# RN831X_RN861X_MCU register map
File version: v0.0.1
CPU: RN831X_RN861X_MCU r1p0, little endian, MPU, no FPU
Registers are 32-bit, read-write, reset 0x0 unless marked. A register's access mark holds for its fields unless they carry their own. Offsets are from the block's base; [hi:lo] are bit positions; {n}, {i} and the like mark numbered series.

## DSP_CORE0 — DSP Module core0
Base 0x2006C000
Same registers: DSP_CORE1 0xA006C000
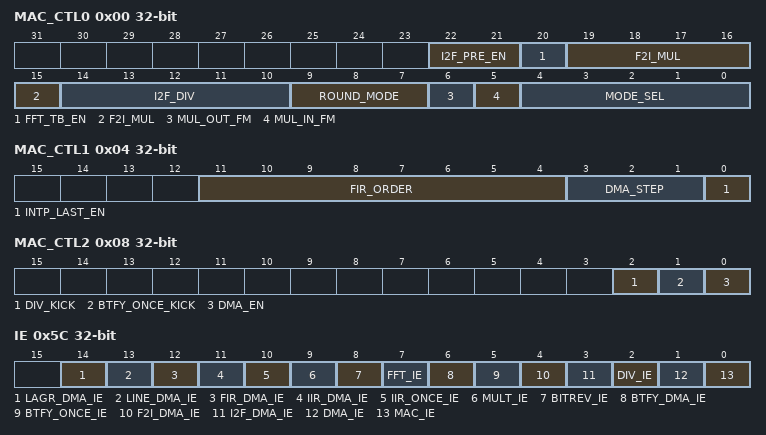
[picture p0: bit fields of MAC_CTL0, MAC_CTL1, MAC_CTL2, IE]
0x00 MAC_CTL0 — Control register_0 of Multiply-Accumulate unit
  [22:21] I2F_PRE_EN — Enable bits of Floating-To-Int preprocess
    0=4BYTE (I2F input data 4 byte available); 1=3BYTE (I2F input data low 3 byte available); 2=2BYTE (I2F input data low 2 byte available); 3=1BYTE (I2F input data low 1 byte available)
  [20] FFT_TB_EN — Enable bit of FFT internal table
  [19:15] F2I_MUL — Magnification order bit of floating point before Floating-To-Int
  [14:10] I2F_DIV — Normalized order bit of floating point after Int-To-Floating
  [9:7] ROUND_MODE — Round mode configuration bits
    0=NEAREST (Select round mode as nearest); 1=ZERO (Select round mode as zero); 2=P_INF (Select round mode as positive infinity); 3=N_INF (Select round mode as negative infinity); 4=UP (Select round mode as nearst up); 5=AWAY (Select round mode as away from zero)
  [6] MUL_OUT_FM — Output format bit of multiplication unit
    0=FLOAT (Select multiplication output format as float); 1=INT (Select multiplication output format as int)
  [5] MUL_IN_FM — Input format bit of multiplication unit
    0=FLOAT (Select multiplication input format as float); 1=INT (Select multiplication input format as int)
  [4:0] MODE_SEL — Select bits of DSP mode
    0=DIS (disable all mode of MAC unit); 1=I2F_ONCE (int to float conversion one-shot mode enable); 2=I2F_DMA (int to float conversion DMA mode enable); 3=F2I_ONCE (float to int conversion one-shot mode enable); 4=F2I_DMA (float to int conversion DMA mode enable); 5=FP_MUL (float multiply mode enable); 6=FP_ADD (float addition mode enable); 7=FP_SUB (float subtraction mode enable); 8=FP_MLAD (float multiplication and addition mode enable); 9=BTFY_ONCE (Butterfly operation unit one-shot mode enable); 10=BTFY_DMA (Butterfly operation unit DMA mode enable); 11=FFT (FFT mode enable); 12=BIT_RV (bit reverse mode enable); 13=IIR_ONCE (2nd IIR filter one-shot mode enable); 14=IIR_DMA (2nd IIR filter DMA mode enable); 15=FIR_DMA (FIR filter mode enable); 16=LINE_INTP (linear interpolation mode enable); 17=LAGR_INTP (Lagrange interpolation mode enable)
0x04 MAC_CTL1 — Control register_1 of Multiply-Accumulate unit
  [11:4] FIR_ORDER — FIR filter order configuration bits
  [3:1] DMA_STEP — Step of DMA read data from SRAM configuration bits (only available for IIR/FIR DMA mode )
    {v}=STEP_{v+1} (Configure DMA data step as {v+1}) (v=0..7)
  [0] INTP_LAST_EN — Interpolation mode using last data of last period enable bit
0x08 MAC_CTL2 access per field — Control register_2 of Multiply-Accumulate unit
  [2] DIV_KICK wo — Enable bit of division unit
  [1] BTFY_ONCE_KICK wo — Enable bit of butterfly once calculate
  [0] DMA_EN rw — Enable bit of DMA
{0xC+4i} MAC_IN{i} access not given (i=0..5) — Input register_{i} of Multiply-Accumulate unit
  [31:0] MAC_IN{i} — Input register_{i} bits of Multiply-Accumulate unit
{0x24+4i} MAC_OUT{i} access not given (i=0..3) — Output register_{i} of Multiply-Accumulate unit
  [31:0] MAC_OUT{i} — Output register_{i} bits of Multiply-Accumulate unit
0x34 DIV_IN0 access not given — Input register_0 of division unit
  [31:0] DIV_IN0 — Input register_0 bits of division unit
0x38 DIV_IN1 access not given — Input register_1 of division unit
  [31:0] DIV_IN1 — Input register_1 bits of division unit
0x3C DIV_OUT0 access not given — Output register_0 of division unit
  [31:0] DIV_OUT0 — Output register_0 bits of division unit
0x40 DMA_SRBADR access not given — Source address register of DMA and FFT real part
  [15:0] DMA_SRBADR — Source address register bits of DMA and FFT real part
0x44 DMA_SIBADR access not given — Source address register of FFT image part
  [15:0] DMA_SIBADR — Source address register bits of FFT image part
0x48 DMA_PRBADR access not given — Address register of phase factor table of real part and FIR mode of parameter A
  [15:0] DMA_PRBADR — Address register bits of phase factor table of real part and FIR mode of parameter A
0x4C DMA_PIBADR access not given — Address register of phase factor table of image part
  [15:0] DMA_PIBADR — Address register bits of phase factor table of image part
0x50 DMA_TRBADR access not given — Target address register of DMA and FFT real part
  [15:0] DMA_TRBADR — Target address register bits of DMA and FFT real part
0x54 DMA_TIBADR access not given — Target address register of FFT image part
  [15:0] DMA_TIBADR — Target address register bits of FFT image part
0x58 DMA_LEN access not given — Length register of DMA
  [9:0] DMA_LEN — Length register bits of DMA
0x5C IE — Interrupt register of DSP
  [14] LAGR_DMA_IE — Interrupt enable bit of lagrange interp DMA
  [13] LINE_DMA_IE — Interrupt enable bit of linear interp DMA
  [12] FIR_DMA_IE — Interrupt enable bit of FIR DMA
  [11] IIR_DMA_IE — Interrupt enable bit of IIR DMA
  [10] IIR_ONCE_IE — Interrupt enable bit of IIR once
  [9] MULT_IE — Interrupt enable bit of multiplication
  [8] BITREV_IE — Interrupt enable bit of bit reverse
  [7] FFT_IE — Interrupt enable bit of FFT
  [6] BTFY_DMA_IE — Interrupt enable bit of butterfly DMA
  [5] BTFY_ONCE_IE — Interrupt enable bit of butterfly once
  [4] F2I_DMA_IE — Interrupt enable bit of Float-To-Int DMA
  [3] I2F_DMA_IE — Interrupt enable bit of Int-To-Float DMA
  [2] DIV_IE — Interrupt enable bit of division
  [1] DMA_IE — Interrupt enable bit of DMA
  [0] MAC_IE — Interrupt enable bit of Multiply-Accumulate
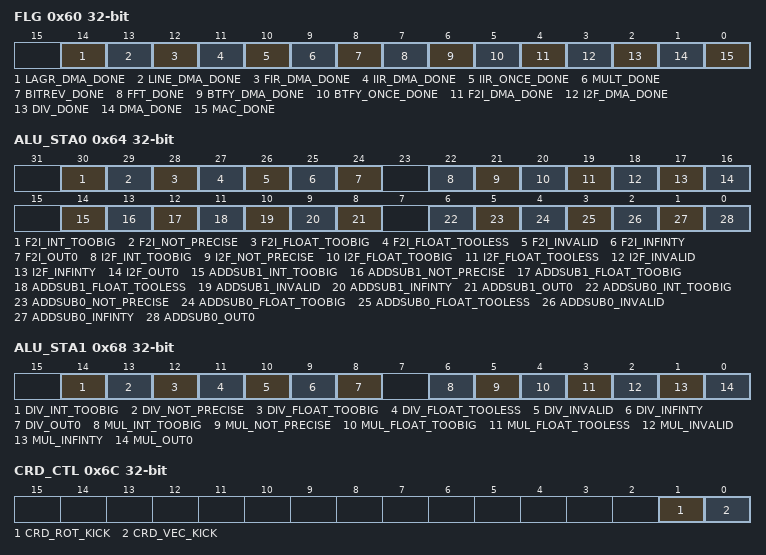
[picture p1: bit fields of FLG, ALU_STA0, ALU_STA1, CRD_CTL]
0x60 FLG — Interrupt flag register of DSP
  [14] LAGR_DMA_DONE write-1-clears — Interrupt flag bit of lagrange interp DMA
  [13] LINE_DMA_DONE write-1-clears — Interrupt flag bit of linear interp DMA
  [12] FIR_DMA_DONE write-1-clears — Interrupt flag bit of FIR DMA
  [11] IIR_DMA_DONE write-1-clears — Interrupt flag bit of IIR DMA
  [10] IIR_ONCE_DONE write-1-clears — Interrupt flag bit of IIR once
  [9] MULT_DONE write-1-clears — Interrupt flag bit of multiplication
  [8] BITREV_DONE write-1-clears — Interrupt flag bit of bit reverse
  [7] FFT_DONE write-1-clears — Interrupt flag bit of FFT
  [6] BTFY_DMA_DONE write-1-clears — Interrupt flag bit of butterfly DMA
  [5] BTFY_ONCE_DONE write-1-clears — Interrupt flag bit of butterfly once
  [4] F2I_DMA_DONE write-1-clears — Interrupt flag bit of Float-To-Int DMA
  [3] I2F_DMA_DONE write-1-clears — Interrupt flag bit of Int-To-Float DMA
  [2] DIV_DONE write-1-clears — Interrupt flag bit of division
  [1] DMA_DONE write-1-clears — Interrupt flag bit of DMA
  [0] MAC_DONE write-1-clears — Interrupt flag bit of Multiply-Accumulate
0x64 ALU_STA0 ro — Status register of Multiply-Accumulate unit and floating unit
  [30] F2I_INT_TOOBIG — F2I int result after rounding has a magnitude greater than the largest representable two's complement integer with the same sign
  [29] F2I_NOT_PRECISE — F2I int or float output is not equal to the infinitely precise result
  [28] F2I_FLOAT_TOOBIG — F2I float number greater than maximum normalized number
  [27] F2I_FLOAT_TOOLESS — F2I float number less than minimum normalized number
  [26] F2I_INVALID — F2I float operation is invalid or one input is NAN
  [25] F2I_INFINTY — F2I float output is infinity
  [24] F2I_OUT0 — F2I int or float point output is zero
  [22] I2F_INT_TOOBIG — I2F int result after rounding has a magnitude greater than the largest representable two's complement integer with the same sign
  [21] I2F_NOT_PRECISE — I2F int or float output is not equal to the infinitely precise result
  [20] I2F_FLOAT_TOOBIG — I2F float number greater than maximum normalized number
  [19] I2F_FLOAT_TOOLESS — I2F float number less than minimum normalized number
  [18] I2F_INVALID — I2F float operation is invalid or one input is NAN
  [17] I2F_INFINTY — I2F float output is infinity
  [16] I2F_OUT0 — I2F int or float point output is zero
  [14] ADDSUB1_INT_TOOBIG — ADDSUB1 int result after rounding has a magnitude greater than the largest representable two's complement integer with the same sign
  [13] ADDSUB1_NOT_PRECISE — ADDSUB1 int or float output is not equal to the infinitely precise result
  [12] ADDSUB1_FLOAT_TOOBIG — ADDSUB1 float number greater than maximum normalized number
  [11] ADDSUB1_FLOAT_TOOLESS — ADDSUB1 float number less than minimum normalized number
  [10] ADDSUB1_INVALID — ADDSUB1 float operation is invalid or one input is NAN
  [9] ADDSUB1_INFINTY — ADDSUB1 float output is infinity
  [8] ADDSUB1_OUT0 — ADDSUB1 int or float point output is zero
  [6] ADDSUB0_INT_TOOBIG — ADDSUB0 int result after rounding has a magnitude greater than the largest representable two's complement integer with the same sign
  [5] ADDSUB0_NOT_PRECISE — ADDSUB0 int or float output is not equal to the infinitely precise result
  [4] ADDSUB0_FLOAT_TOOBIG — ADDSUB0 float number greater than maximum normalized number
  [3] ADDSUB0_FLOAT_TOOLESS — ADDSUB0 float number less than minimum normalized number
  [2] ADDSUB0_INVALID — ADDSUB0 float operation is invalid or one input is NAN
  [1] ADDSUB0_INFINTY — ADDSUB0 float output is infinity
  [0] ADDSUB0_OUT0 — ADDSUB0 int or float point output is zero
0x68 ALU_STA1 ro — Status register of multiplication and division units
  [14] DIV_INT_TOOBIG — DIV int result after rounding has a magnitude greater than the largest representable two's complement integer with the same sign
  [13] DIV_NOT_PRECISE — DIV int or float output is not equal to the infinitely precise result
  [12] DIV_FLOAT_TOOBIG — DIV float number greater than maximum normalized number
  [11] DIV_FLOAT_TOOLESS — DIV float number less than minimum normalized number
  [10] DIV_INVALID — DIV float operation is invalid or one input is NAN
  [9] DIV_INFINTY — DIV float output is infinity
  [8] DIV_OUT0 — DIV inte or float point output is zero
  [6] MUL_INT_TOOBIG — MUL int result after rounding has a magnitude greater than the largest representable two's complement integer with the same sign
  [5] MUL_NOT_PRECISE — MUL int or float output is not equal to the infinitely precise result
  [4] MUL_FLOAT_TOOBIG — MUL float number greater than maximum normalized number
  [3] MUL_FLOAT_TOOLESS — MUL float number less than minimum normalized number
  [2] MUL_INVALID — MUL float operation is invalid or one input is NAN
  [1] MUL_INFINTY — MUL float output is infinity
  [0] MUL_OUT0 — MUL inte or float point output is zero
0x6C CRD_CTL wo — Control register of cordic
  [1] CRD_ROT_KICK — DSP cordic rotation mode start bit
  [0] CRD_VEC_KICK — DSP cordic vector mode start bit
0x70 CRD_XIN access not given — Input register of data X of cordic rotation mode
  [31:0] X_IN — Input register bits of data X of cordic rotation mode
0x74 CRD_YIN access not given — Input register of data Y of cordic rotation mode
  [31:0] Y_IN — Input register bits of data Y of cordic rotation mode
0x78 CRD_AMP access not given — Output register of amplitude of cordic rotation mode
  [31:0] AMP_OUT — Output register bits of amplitude of cordic rotation mode
0x7C CRD_PHASE access not given — Output register of phase of cordic rotation mode
  [31:0] PHASE_OUT — Output register bits of phase of cordic rotation mode
0x80 CRD_ANGLE access not given — Input register of angle of cordic vector mode
  [31:0] ANGLE_IN — Input register bits of angle of cordic vector mode
0x84 CRD_COSINE access not given — Output register of cosine of cordic vector mode
  [31:0] COSINE_OUT — Output register bits of cosine of cordic vector mode
0x88 CRD_SINE access not given — Output register of sine of cordic vector mode
  [31:0] SINE_OUT — Output register bits of sine of cordic vector mode
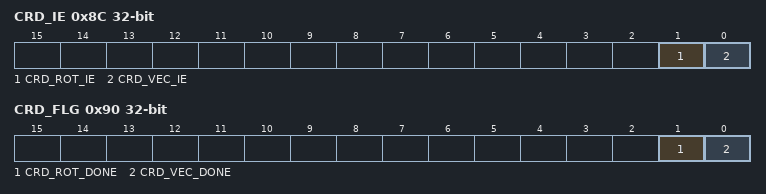
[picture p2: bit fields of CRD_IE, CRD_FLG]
0x8C CRD_IE — Interrupt register of cordic
  [1] CRD_ROT_IE — Cordic rotation mode completion interrupt enable bit
  [0] CRD_VEC_IE — Cordic vector mode completion interrupt enable bit
0x90 CRD_FLG — Interrupt flag register of cordic
  [1] CRD_ROT_DONE write-1-clears — Cordic rotation operation completion flag
  [0] CRD_VEC_DONE write-1-clears — Cordic vector operation completion flag
0x94 INTP_LEN access not given — Length register of interp
  [12:0] INTP_LEN — Length register bits of interp
0x98 INTP_LOC access not given — Current location register of interp
  [31:0] INTP_LOC — Current location register bits of interp
0x9C INTP_STEP access not given — Step register of interp
  [31:0] INTP_STEP — Step register bits of interp
